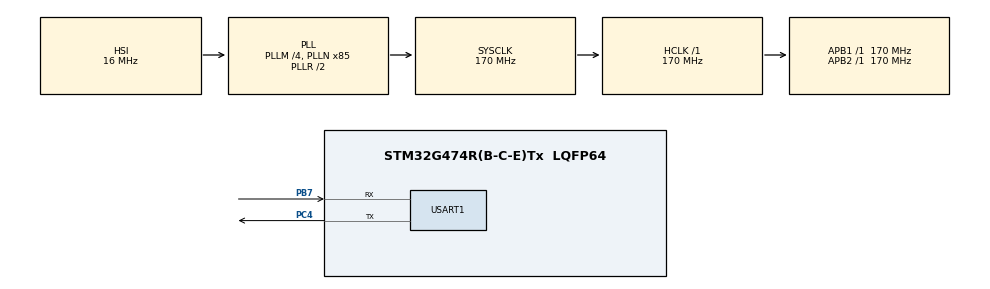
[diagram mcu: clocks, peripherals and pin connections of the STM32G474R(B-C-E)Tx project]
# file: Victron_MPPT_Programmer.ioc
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Dma.Request0=USART1_RX
Dma.USART1_RX.0.Direction=DMA_PERIPH_TO_MEMORY
Dma.USART1_RX.0.EventEnable=DISABLE
Dma.USART1_RX.0.Instance=DMA1_Channel1
Dma.USART1_RX.0.MemDataAlignment=DMA_MDATAALIGN_BYTE
Dma.USART1_RX.0.MemInc=DMA_MINC_ENABLE
Dma.USART1_RX.0.Mode=DMA_NORMAL
Dma.USART1_RX.0.PeriphDataAlignment=DMA_PDATAALIGN_BYTE
Dma.USART1_RX.0.PeriphInc=DMA_PINC_DISABLE
Dma.USART1_RX.0.Polarity=HAL_DMAMUX_REQ_GEN_RISING
Dma.USART1_RX.0.Priority=DMA_PRIORITY_LOW
Dma.USART1_RX.0.RequestNumber=1
Dma.USART1_RX.0.SignalID=NONE
Dma.USART1_RX.0.SyncEnable=DISABLE
Dma.USART1_RX.0.SyncPolarity=HAL_DMAMUX_SYNC_NO_EVENT
Dma.USART1_RX.0.SyncRequestNumber=1
Dma.USART1_RX.0.SyncSignalID=NONE
Mcu.Family=STM32G4
Mcu.Name=STM32G474R(B-C-E)Tx
Mcu.Package=LQFP64
NUCLEO-G474RE.BUTTON=1
NUCLEO-G474RE.LD2=true
NUCLEO-G474RE.VCP=true
NVIC.DMA1_Channel1_IRQn=true\:0\:0\:false\:false\:true\:false\:true\:true
NVIC.EXTI15_10_IRQn=true\:0\:0\:false\:false\:true\:false\:true\:true
NVIC.PriorityGroup=NVIC_PRIORITYGROUP_4
PA13.GPIO_Label=T_SWDIO
PA13.Signal=SYS_JTMS-SWDIO
PA14.GPIO_Label=T_SWCLK
PA14.Signal=SYS_JTCK-SWCLK
PA2.Signal=LPUART1_TX
PA3.Signal=LPUART1_RX
PB3.GPIO_Label=T_SWO
PB3.Signal=SYS_JTDO-SWO
PB7.Mode=Asynchronous
PB7.Signal=USART1_RX
PC14-OSC32_IN.GPIO_Label=RCC_OSC32_IN
PC14-OSC32_IN.Signal=RCC_OSC32_IN
PC15-OSC32_OUT.GPIO_Label=RCC_OSC32_OUT
PC15-OSC32_OUT.Signal=RCC_OSC32_OUT
PC4.Mode=Asynchronous
PC4.Signal=USART1_TX
PF0-OSC_IN.GPIO_Label=RCC_OSC_IN
PF0-OSC_IN.Signal=RCC_OSC_IN
PF1-OSC_OUT.GPIO_Label=RCC_OSC_OUT
PF1-OSC_OUT.Signal=RCC_OSC_OUT
ProjectManager.HeapSize=0x200
ProjectManager.StackSize=0x400
ProjectManager.TargetToolchain=CMake
RCC.ADC12Freq_Value=170000000
RCC.ADC345Freq_Value=170000000
RCC.AHBFreq_Value=170000000
RCC.APB1Freq_Value=170000000
RCC.APB1TimFreq_Value=170000000
RCC.APB2Freq_Value=170000000
RCC.APB2TimFreq_Value=170000000
RCC.CortexFreq_Value=170000000
RCC.EXTERNAL_CLOCK_VALUE=12288000
RCC.HCLKFreq_Value=170000000
RCC.HSE_VALUE=24000000
RCC.HSI48_VALUE=48000000
RCC.HSI_VALUE=16000000
RCC.LSE_VALUE=32768
RCC.PLLM=RCC_PLLM_DIV4
RCC.PLLN=85
RCC.RTCClockSelection=RCC_RTCCLKSOURCE_LSE
RCC.SYSCLKFreq_VALUE=170000000
RCC.SYSCLKSource=RCC_SYSCLKSOURCE_PLLCLK
RCC.USBFreq_Value=170000000
RCC.VCOOutputFreq_Value=340000000
USART1.VirtualMode-Asynchronous=VM_ASYNC
VP_NUCLEO-G474RE_VS_BSP_COMMON.Mode=COMMON
VP_SYS_VS_DBSignals.Mode=DisableDeadBatterySignals
board=NUCLEO-G474RE

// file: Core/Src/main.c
/* USER CODE BEGIN Header */
/**
  ******************************************************************************
  * @file           : main.c
  * @brief          : Main program body
  ******************************************************************************
  * @attention
  *
  * Copyright (c) 2026 STMicroelectronics.
  * All rights reserved.
  *
  * This software is licensed under terms that can be found in the LICENSE file
  * in the root directory of this software component.
  * If no LICENSE file comes with this software, it is provided AS-IS.
  *
  ******************************************************************************
  */
/* USER CODE END Header */
#include "main.h"

#include <stdbool.h>

#include "MPPT_HEX_parsing.h"

COM_InitTypeDef BspCOMInit;
UART_HandleTypeDef huart1;
DMA_HandleTypeDef hdma_usart1_rx;

/* USER CODE BEGIN PV */

// MPPT HEX COMMANDS
//DIAGNOSTICS
uint8_t getError[11]                  = {':','7','D','A', 'E', 'D','0','0','8','7', '\n'};
//TODO: make this command
uint8_t getState[11]                  = {':','7','0','0', '0', '0','0','0','0','0', '\n'};
uint8_t getPanelPower[11]             = {':','7','B','C', 'E', 'D','0','0','A','5', '\n'};
uint8_t getPanelVoltage[11]           = {':','7','D','5', 'E', 'D','0','0','8','C', '\n'};

//SETTINGS
//GET
uint8_t getFloatSettingVoltage[11]    = {':','7','F','6', 'E', 'D','0','0','6','B', '\n'};
uint8_t getRebulkSettingsVoltage[11]  = {':','7','2','E', 'E', 'D','0','0','3','2', '\n'};
uint8_t getBatteryMaximumCurrent[11]  = {':','7', 'F', '0', 'E', 'D', '0', '0', '7', '1','\n'};

//SET

uint8_t setBatteryTypeUserDefined[13] = {':','8','F', '1', 'E', 'D','0','0','F','F','7','0','\n'};        // set to 0xFF - userDefined
uint8_t setFloatSettingVoltage[15]    = {':','8','F','6', 'E', 'D','0','0','F','8','1','6','5','C','\n'}; // set to 58.8
uint8_t setfactoryReset[9]            = {':','8','0','4', '0', '0','4','9', '\n'};

// UART buffers and MPPT parsing States
#define MPPT_BUF_SIZE 256
uint8_t MPPT_buf[MPPT_BUF_SIZE];
uint8_t MPPT_buf_main[MPPT_BUF_SIZE];
uint8_t mpptHex[30];

uint32_t lastMPPTread = 0;

bool frameDone = false;
/* USER CODE END PV */

void SystemClock_Config(void);
static void MX_GPIO_Init(void);
static void MX_DMA_Init(void);
static void MX_USART1_UART_Init(void);

/* USER CODE BEGIN 0 */
void HAL_UARTEx_RxEventCallback(UART_HandleTypeDef *huart, uint16_t Size) {
  if (huart->Instance == USART1) { //MPPT
    // parseMPPTHex(&data, MPPT_buf, MPPT_BUF_SIZE);

    // clean buffer: set to 0
    for (uint16_t i = 0; i < MPPT_BUF_SIZE; i++) {
      MPPT_buf[i] = 0;
    }
  }
}
/* USER CODE END 0 */

int main(void)
{

  /* MCU Configuration--------------------------------------------------------*/

  /* Reset of all peripherals, Initializes the Flash interface and the Systick. */
  HAL_Init();

  /* Configure the system clock */
  SystemClock_Config();

  /* Initialize all configured peripherals */
  MX_GPIO_Init();
  MX_DMA_Init();
  MX_USART1_UART_Init();
  /* USER CODE BEGIN 2 */

  // init RX_UART
  HAL_UARTEx_ReceiveToIdle_DMA(&huart1, MPPT_buf, MPPT_BUF_SIZE);

  /* USER CODE END 2 */

  /* Initialize led */
  BSP_LED_Init(LED_GREEN);

  /* Initialize USER push-button, will be used to trigger an interrupt each time it's pressed.*/
  BSP_PB_Init(BUTTON_USER, BUTTON_MODE_EXTI);

  /* Initialize COM1 port (115200, 8 bits (7-bit data + 1 stop bit), no parity */
  BspCOMInit.BaudRate   = 115200;
  BspCOMInit.WordLength = COM_WORDLENGTH_8B;
  BspCOMInit.StopBits   = COM_STOPBITS_1;
  BspCOMInit.Parity     = COM_PARITY_NONE;
  BspCOMInit.HwFlowCtl  = COM_HWCONTROL_NONE;
  if (BSP_COM_Init(COM1, &BspCOMInit) != BSP_ERROR_NONE)
  {
    Error_Handler();
  }

  /* Infinite loop */
  /* USER CODE BEGIN WHILE */
  uint8_t SettingBuf[15];
  // Battery type, 0xFF is user defined
  buildMPPTHexCommand(SettingBuf, 15, 8, 0xEDF1, 0xFF, MPPT_uint8);
  HAL_UART_Transmit(&huart1, SettingBuf, 15, 1000);
  // Battery voltage, 48V
  buildMPPTHexCommand(SettingBuf, 15, 8, 0xEDEF, 48, MPPT_uint8);
  HAL_UART_Transmit(&huart1, SettingBuf, 15, 1000);
  // Battery temp. compensation, 0mv (disable for lithium batteries)
  buildMPPTHexCommand(SettingBuf, 15, 8, 0xEDF2, 0, MPPT_uint16);
  HAL_UART_Transmit(&huart1, SettingBuf, 15, 1000);
  // Battery float voltage, 58.8
  buildMPPTHexCommand(SettingBuf, 15, 8, 0xEDF6, 5880, MPPT_uint16);
  HAL_UART_Transmit(&huart1, SettingBuf, 15, 1000);
  // Battery absorption voltage, 58.8
  buildMPPTHexCommand(SettingBuf, 15, 8, 0xEDF7, 5880, MPPT_uint16);
  HAL_UART_Transmit(&huart1, SettingBuf, 15, 1000);
  while (1)
  {
    if (HAL_GetTick() - lastMPPTread > 1000) {
      //get status of MPPT during programming
      HAL_UART_Transmit(&huart1, getError, 11, 1000);
      HAL_UART_Transmit(&huart1, getState, 11, 1000);

      lastMPPTread = HAL_GetTick();
    }
    /* USER CODE END WHILE */

  }
}

void SystemClock_Config(void)
{
  RCC_OscInitTypeDef RCC_OscInitStruct = {0};
  RCC_ClkInitTypeDef RCC_ClkInitStruct = {0};

  /** Configure the main internal regulator output voltage
  */
  HAL_PWREx_ControlVoltageScaling(PWR_REGULATOR_VOLTAGE_SCALE1_BOOST);

  /** Initializes the RCC Oscillators according to the specified parameters
  * in the RCC_OscInitTypeDef structure.
  */
  RCC_OscInitStruct.OscillatorType = RCC_OSCILLATORTYPE_HSI;
  RCC_OscInitStruct.HSIState = RCC_HSI_ON;
  RCC_OscInitStruct.HSICalibrationValue = RCC_HSICALIBRATION_DEFAULT;
  RCC_OscInitStruct.PLL.PLLState = RCC_PLL_ON;
  RCC_OscInitStruct.PLL.PLLSource = RCC_PLLSOURCE_HSI;
  RCC_OscInitStruct.PLL.PLLM = RCC_PLLM_DIV4;
  RCC_OscInitStruct.PLL.PLLN = 85;
  RCC_OscInitStruct.PLL.PLLP = RCC_PLLP_DIV2;
  RCC_OscInitStruct.PLL.PLLQ = RCC_PLLQ_DIV2;
  RCC_OscInitStruct.PLL.PLLR = RCC_PLLR_DIV2;
  if (HAL_RCC_OscConfig(&RCC_OscInitStruct) != HAL_OK)
  {
    Error_Handler();
  }

  /** Initializes the CPU, AHB and APB buses clocks
  */
  RCC_ClkInitStruct.ClockType = RCC_CLOCKTYPE_HCLK|RCC_CLOCKTYPE_SYSCLK
                              |RCC_CLOCKTYPE_PCLK1|RCC_CLOCKTYPE_PCLK2;
  RCC_ClkInitStruct.SYSCLKSource = RCC_SYSCLKSOURCE_PLLCLK;
  RCC_ClkInitStruct.AHBCLKDivider = RCC_SYSCLK_DIV1;
  RCC_ClkInitStruct.APB1CLKDivider = RCC_HCLK_DIV1;
  RCC_ClkInitStruct.APB2CLKDivider = RCC_HCLK_DIV1;

  if (HAL_RCC_ClockConfig(&RCC_ClkInitStruct, FLASH_LATENCY_4) != HAL_OK)
  {
    Error_Handler();
  }
}

static void MX_USART1_UART_Init(void)
{

  huart1.Instance = USART1;
  huart1.Init.BaudRate = 115200;
  huart1.Init.WordLength = UART_WORDLENGTH_8B;
  huart1.Init.StopBits = UART_STOPBITS_1;
  huart1.Init.Parity = UART_PARITY_NONE;
  huart1.Init.Mode = UART_MODE_TX_RX;
  huart1.Init.HwFlowCtl = UART_HWCONTROL_NONE;
  huart1.Init.OverSampling = UART_OVERSAMPLING_16;
  huart1.Init.OneBitSampling = UART_ONE_BIT_SAMPLE_DISABLE;
  huart1.Init.ClockPrescaler = UART_PRESCALER_DIV1;
  huart1.AdvancedInit.AdvFeatureInit = UART_ADVFEATURE_NO_INIT;
  if (HAL_UART_Init(&huart1) != HAL_OK)
  {
    Error_Handler();
  }
  if (HAL_UARTEx_SetTxFifoThreshold(&huart1, UART_TXFIFO_THRESHOLD_1_8) != HAL_OK)
  {
    Error_Handler();
  }
  if (HAL_UARTEx_SetRxFifoThreshold(&huart1, UART_RXFIFO_THRESHOLD_1_8) != HAL_OK)
  {
    Error_Handler();
  }
  if (HAL_UARTEx_DisableFifoMode(&huart1) != HAL_OK)
  {
    Error_Handler();
  }

}

static void MX_DMA_Init(void)
{

  /* DMA controller clock enable */
  __HAL_RCC_DMAMUX1_CLK_ENABLE();
  __HAL_RCC_DMA1_CLK_ENABLE();

  /* DMA interrupt init */
  /* DMA1_Channel1_IRQn interrupt configuration */
  HAL_NVIC_SetPriority(DMA1_Channel1_IRQn, 0, 0);
  HAL_NVIC_EnableIRQ(DMA1_Channel1_IRQn);

}

static void MX_GPIO_Init(void)
{

  /* GPIO Ports Clock Enable */
  __HAL_RCC_GPIOC_CLK_ENABLE();
  __HAL_RCC_GPIOF_CLK_ENABLE();
  __HAL_RCC_GPIOA_CLK_ENABLE();
  __HAL_RCC_GPIOB_CLK_ENABLE();

}

void Error_Handler(void)
{
  __disable_irq();
  while (1)
  {
  }
}
